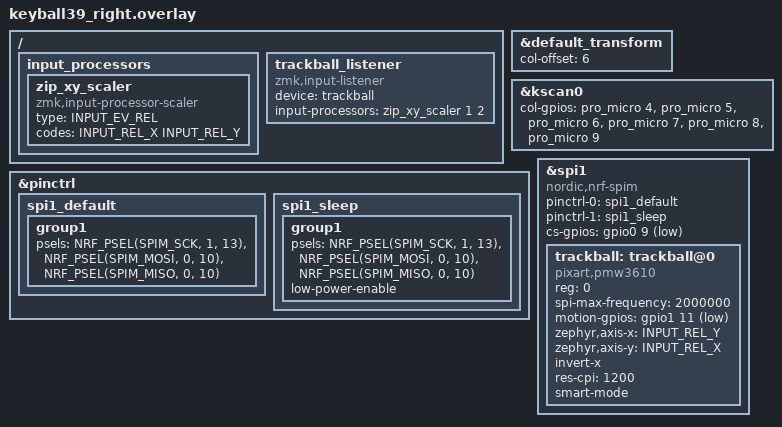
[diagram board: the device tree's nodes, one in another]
/*
 * Copyright (c) 2020 ZMK Contributors
 *
 * SPDX-License-Identifier: MIT
 */

#include "keyball39.dtsi"

&default_transform {
    col-offset = <6>;
};

&kscan0 {
    col-gpios
        = <&pro_micro 4 GPIO_ACTIVE_HIGH>
        , <&pro_micro 5 GPIO_ACTIVE_HIGH>
        , <&pro_micro 6 GPIO_ACTIVE_HIGH>
        , <&pro_micro 7 GPIO_ACTIVE_HIGH>
        , <&pro_micro 8 GPIO_ACTIVE_HIGH>
        , <&pro_micro 9 GPIO_ACTIVE_HIGH>
        ;
};

&pinctrl {
    spi1_default: spi1_default {
        group1 {
            psels = <NRF_PSEL(SPIM_SCK, 1, 13)>,
                <NRF_PSEL(SPIM_MOSI, 0, 10)>,
                <NRF_PSEL(SPIM_MISO, 0, 10)>;
        };
    };

    spi1_sleep: spi1_sleep {
        group1 {
            psels = <NRF_PSEL(SPIM_SCK, 1, 13)>,
                <NRF_PSEL(SPIM_MOSI, 0, 10)>,
                <NRF_PSEL(SPIM_MISO, 0, 10)>;
            low-power-enable;
        };
    };
};

&spi1 {
    status = "okay";
    compatible = "nordic,nrf-spim";
    pinctrl-0 = <&spi1_default>;
    pinctrl-1 = <&spi1_sleep>;
    pinctrl-names = "default", "sleep";
    cs-gpios = <&gpio0 9 GPIO_ACTIVE_LOW>;

    trackball: trackball@0 {
        status = "okay";
        compatible = "pixart,pmw3610";
        reg = <0>;
        spi-max-frequency = <2000000>;
        motion-gpios = <&gpio1 11 (GPIO_ACTIVE_LOW | GPIO_PULL_UP)>;

        zephyr,axis-x = <INPUT_REL_Y>;
        zephyr,axis-y = <INPUT_REL_X>;
        invert-x;

        /* 1600 CPI with 1/2 scaler = ~800 CPI effective cursor speed.
           Noise filtering: sensor delta-1 / 2 = 0 (integer truncated),
           so resting noise never moves the cursor or triggers layer switch.
           Real movement (delta 2+) / 2 = 1+ passes through correctly. */
        res-cpi = <1200>;
        smart-mode;
    };
};

/ {
    input_processors {
        zip_xy_scaler: zip_xy_scaler {
            compatible = "zmk,input-processor-scaler";
            #input-processor-cells = <2>;
            type = <INPUT_EV_REL>;
            codes = <INPUT_REL_X INPUT_REL_Y>;
        };

        /* AUTO MOUSE LAYER DISABLED - workaround for worn trackball socket
           causing phantom layer triggers from ball microvibration.
           Re-enable once socket is reprinted. Use <lt 4 TAB> to switch
           to mouse layer manually for clicks in the meantime.
        zip_temp_layer: zip_temp_layer {
            compatible = "zmk,input-processor-temp-layer";
            #input-processor-cells = <2>;
            require-prior-idle-ms = <800>;
        };
        */
    };

    trackball_listener: trackball_listener {
        compatible = "zmk,input-listener";
        device = <&trackball>;
        input-processors = <
            &zip_xy_scaler 1 2
            /* &zip_temp_layer 4 630 -- disabled, see above */
        >;
    };
};
